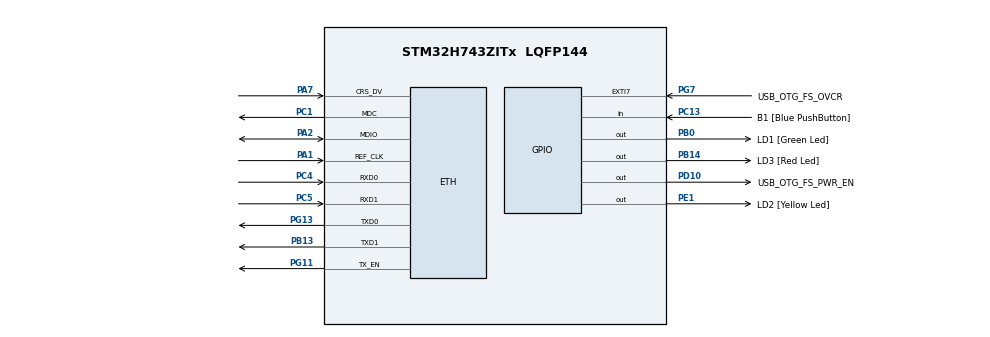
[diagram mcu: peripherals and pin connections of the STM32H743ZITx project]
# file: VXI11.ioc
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CORTEX_M7.AccessPermission_S-Cortex_Memory_Protection_Unit_Region1_Settings_S=MPU_REGION_FULL_ACCESS
CORTEX_M7.AccessPermission_S-Cortex_Memory_Protection_Unit_Region2_Settings_S=MPU_REGION_FULL_ACCESS
CORTEX_M7.BaseAddress_S-Cortex_Memory_Protection_Unit_Region1_Settings_S=0x30020000
CORTEX_M7.BaseAddress_S-Cortex_Memory_Protection_Unit_Region2_Settings_S=0x30040000
CORTEX_M7.CPU_DCache=Enabled
CORTEX_M7.CPU_ICache=Enabled
CORTEX_M7.DisableExec_S-Cortex_Memory_Protection_Unit_Region1_Settings_S=MPU_INSTRUCTION_ACCESS_DISABLE
CORTEX_M7.DisableExec_S-Cortex_Memory_Protection_Unit_Region2_Settings_S=MPU_INSTRUCTION_ACCESS_DISABLE
CORTEX_M7.Enable_S-Cortex_Memory_Protection_Unit_Region1_Settings_S=MPU_REGION_ENABLE
CORTEX_M7.Enable_S-Cortex_Memory_Protection_Unit_Region2_Settings_S=MPU_REGION_ENABLE
CORTEX_M7.IsBufferable_S-Cortex_Memory_Protection_Unit_Region2_Settings_S=MPU_ACCESS_BUFFERABLE
CORTEX_M7.IsShareable_S-Cortex_Memory_Protection_Unit_Region2_Settings_S=MPU_ACCESS_SHAREABLE
CORTEX_M7.Size_S-Cortex_Memory_Protection_Unit_Region1_Settings_S=MPU_REGION_SIZE_128KB
CORTEX_M7.Size_S-Cortex_Memory_Protection_Unit_Region2_Settings_S=MPU_REGION_SIZE_512B
CORTEX_M7.TypeExtField_S-Cortex_Memory_Protection_Unit_Region1_Settings_S=MPU_TEX_LEVEL1
CORTEX_M7.default_mode_Activation=1
ETH.MediaInterface=HAL_ETH_RMII_MODE
FREERTOS.Tasks01=defaultTask,0,512,StartDefaultTask,Default,NULL,Static,defaultTaskBuffer,defaultTaskControlBlock
FREERTOS.configENABLE_FPU=1
FREERTOS.configMINIMAL_STACK_SIZE=512
FREERTOS.configUSE_NEWLIB_REENTRANT=1
LWIP.BSP.number=1
LWIP.DEFAULT_THREAD_PRIO=6
LWIP.DEFAULT_THREAD_STACKSIZE=1024
LWIP.IP_ADDRESS=192.168.001.002
LWIP.LWIP_DHCP=0
LWIP.LWIP_RAM_HEAP_POINTER=0x30020000
LWIP.LWIP_SOCKET=0
LWIP.MEMP_NUM_LOCALHOSTLIST=1
LWIP.MEMP_NUM_PBUF=20
LWIP.MEMP_NUM_RAW_PCB=20
LWIP.MEMP_NUM_TCP_PCB=20
LWIP.MEMP_NUM_TCP_SEG=20
LWIP.MEMP_NUM_UDP_PCB=20
LWIP.MEM_SIZE=131048
LWIP.NETMASK_ADDRESS=255.255.255.000
LWIP.PBUF_POOL_BUFSIZE=1024
LWIP.TCPIP_MBOX_SIZE=12
LWIP.TCPIP_THREAD_PRIO=6
LWIP.TCPIP_THREAD_STACKSIZE=1024
LWIP.TCP_MSS=1460
LWIP.TCP_SND_BUF=5840
LWIP.TCP_SND_QUEUELEN=16
LWIP.TCP_WND=5840
LWIP.Version=v2.1.2_Cube
LWIP0.BSP.STBoard=false
LWIP0.BSP.api=BSP_COMPONENT_DRIVER
LWIP0.BSP.component=LAN8742
LWIP0.BSP.instance=LAN8742
LWIP0.BSP.name=Driver_PHY
LWIP0.BSP.semaphore=S_LAN8742
LWIP0.BSP.solution=LAN8742
Mcu.Family=STM32H7
Mcu.Name=STM32H743ZITx
Mcu.Package=LQFP144
NVIC.ETH_IRQn=true\:5\:0\:false\:false\:true\:true\:true\:true\:true
NVIC.PriorityGroup=NVIC_PRIORITYGROUP_4
NVIC.TIM1_UP_IRQn=true\:15\:0\:false\:false\:true\:false\:false\:true\:true
NVIC.TimeBase=TIM1_UP_IRQn
NVIC.TimeBaseIP=TIM1
PA1.GPIO_Speed=GPIO_SPEED_FREQ_VERY_HIGH
PA1.Mode=RMII
PA1.Signal=ETH_REF_CLK
PA11.Signal=USB_OTG_FS_DM
PA12.Signal=USB_OTG_FS_DP
PA2.GPIO_Speed=GPIO_SPEED_FREQ_VERY_HIGH
PA2.Mode=RMII
PA2.Signal=ETH_MDIO
PA7.GPIO_Speed=GPIO_SPEED_FREQ_VERY_HIGH
PA7.Mode=RMII
PA7.Signal=ETH_CRS_DV
PA8.Signal=USB_OTG_FS_SOF
PA9.Signal=USB_OTG_FS_VBUS
PB0.GPIO_Label=LD1 [Green Led]
PB0.Signal=GPIO_Output
PB13.GPIO_Speed=GPIO_SPEED_FREQ_VERY_HIGH
PB13.Mode=RMII
PB13.Signal=ETH_TXD1
PB14.GPIO_Label=LD3 [Red Led]
PB14.Signal=GPIO_Output
PC1.GPIO_Speed=GPIO_SPEED_FREQ_VERY_HIGH
PC1.Mode=RMII
PC1.Signal=ETH_MDC
PC13.GPIO_Label=B1 [Blue PushButton]
PC13.Signal=GPIO_Input
PC14-OSC32_IN\ (OSC32_IN).Mode=LSE-External-Oscillator
PC14-OSC32_IN\ (OSC32_IN).Signal=RCC_OSC32_IN
PC15-OSC32_OUT\ (OSC32_OUT).Mode=LSE-External-Oscillator
PC15-OSC32_OUT\ (OSC32_OUT).Signal=RCC_OSC32_OUT
PC4.GPIO_Speed=GPIO_SPEED_FREQ_VERY_HIGH
PC4.Mode=RMII
PC4.Signal=ETH_RXD0
PC5.GPIO_Speed=GPIO_SPEED_FREQ_VERY_HIGH
PC5.Mode=RMII
PC5.Signal=ETH_RXD1
PD10.GPIO_Label=USB_OTG_FS_PWR_EN
PD10.Signal=GPIO_Output
PD8.GPIO_Label=STLINK_RX
PD8.Signal=USART3_TX
PD9.GPIO_Label=STLINK_TX
PD9.Signal=USART3_RX
PE1.GPIO_Label=LD2 [Yellow Led]
PE1.Signal=GPIO_Output
PG11.GPIO_Speed=GPIO_SPEED_FREQ_VERY_HIGH
PG11.Mode=RMII
PG11.Signal=ETH_TX_EN
PG13.GPIO_Speed=GPIO_SPEED_FREQ_VERY_HIGH
PG13.Mode=RMII
PG13.Signal=ETH_TXD0
PG7.GPIO_Label=USB_OTG_FS_OVCR
PG7.Signal=GPXTI7
PH0-OSC_IN\ (PH0).Mode=HSE-External-Clock-Source
PH0-OSC_IN\ (PH0).Signal=RCC_OSC_IN
PH1-OSC_OUT\ (PH1).Signal=RCC_OSC_OUT
ProjectManager.HeapSize=0x200
ProjectManager.StackSize=0x400
ProjectManager.TargetToolchain=STM32CubeIDE
RCC.ADCFreq_Value=16125000
RCC.APB1Freq_Value=120000000
RCC.APB2Freq_Value=120000000
RCC.APB3Freq_Value=120000000
RCC.APB4Freq_Value=120000000
RCC.CortexFreq_Value=480000000
RCC.D1PPRE=RCC_APB3_DIV2
RCC.D2PPRE1=RCC_APB1_DIV2
RCC.D2PPRE2=RCC_APB2_DIV2
RCC.D3PPRE=RCC_APB4_DIV2
RCC.DIVM1=1
RCC.DIVN1=120
RCC.DIVQ1=4
RCC.HCLKFreq_Value=240000000
RCC.HPRE=RCC_HCLK_DIV2
RCC.HSE_VALUE=8000000
RCC.PLLFRACN=0
RCC.PLLSourceVirtual=RCC_PLLSOURCE_HSE
RCC.PWR_Regulator_Voltage_Scale=PWR_REGULATOR_VOLTAGE_SCALE0
RCC.SYSCLKFreq_VALUE=480000000
RCC.SYSCLKSource=RCC_SYSCLKSOURCE_PLLCLK
RCC.USBFreq_Value=240000000
VP_FREERTOS_VS_CMSIS_V1.Mode=CMSIS_V1
VP_LWIP_VS_Enabled.Mode=Enabled
VP_SYS_VS_tim1.Mode=TIM1
board=NUCLEO-H743ZI2

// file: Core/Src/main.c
/* USER CODE BEGIN Header */
/**
  ******************************************************************************
  * @file           : main.c
  * @brief          : Main program body
  ******************************************************************************
  * @attention
  *
  * Copyright (c) 2024 STMicroelectronics.
  * All rights reserved.
  *
  * This software is licensed under terms that can be found in the LICENSE file
  * in the root directory of this software component.
  * If no LICENSE file comes with this software, it is provided AS-IS.
  *
  ******************************************************************************
  */
/* USER CODE END Header */
#include "main.h"
#include "cmsis_os.h"
#include "lwip.h"

/* USER CODE BEGIN Includes */
#include "portmap.h"
#include "vxi11.h"
/* USER CODE END Includes */

osThreadId defaultTaskHandle;
uint32_t defaultTaskBuffer[ 512 ];
osStaticThreadDef_t defaultTaskControlBlock;

void SystemClock_Config(void);
static void MPU_Config(void);
static void MX_GPIO_Init(void);
void StartDefaultTask(void const * argument);

int main(void)
{

  /* MPU Configuration--------------------------------------------------------*/
  MPU_Config();

  /* Enable the CPU Cache */

  /* Enable I-Cache---------------------------------------------------------*/
  SCB_EnableICache();

  /* Enable D-Cache---------------------------------------------------------*/
  SCB_EnableDCache();

  /* MCU Configuration--------------------------------------------------------*/

  /* Reset of all peripherals, Initializes the Flash interface and the Systick. */
  HAL_Init();

  /* Configure the system clock */
  SystemClock_Config();

  /* Initialize all configured peripherals */
  MX_GPIO_Init();

  /* Create the thread(s) */
  /* definition and creation of defaultTask */
  osThreadStaticDef(defaultTask, StartDefaultTask, osPriorityNormal, 0, 512, defaultTaskBuffer, &defaultTaskControlBlock);
  defaultTaskHandle = osThreadCreate(osThread(defaultTask), NULL);

  /* Start scheduler */
  osKernelStart();

  /* We should never get here as control is now taken by the scheduler */

  /* Infinite loop */
  while (1)
  {

  }
}

void SystemClock_Config(void)
{
  LL_FLASH_SetLatency(LL_FLASH_LATENCY_4);
  while(LL_FLASH_GetLatency()!= LL_FLASH_LATENCY_4)
  {
  }
  LL_PWR_ConfigSupply(LL_PWR_LDO_SUPPLY);
  LL_PWR_SetRegulVoltageScaling(LL_PWR_REGU_VOLTAGE_SCALE0);
  while (LL_PWR_IsActiveFlag_VOS() == 0)
  {
  }
  LL_RCC_HSE_EnableBypass();
  LL_RCC_HSE_Enable();

   /* Wait till HSE is ready */
  while(LL_RCC_HSE_IsReady() != 1)
  {

  }
  LL_RCC_PLL_SetSource(LL_RCC_PLLSOURCE_HSE);
  LL_RCC_PLL1P_Enable();
  LL_RCC_PLL1_SetVCOInputRange(LL_RCC_PLLINPUTRANGE_8_16);
  LL_RCC_PLL1_SetVCOOutputRange(LL_RCC_PLLVCORANGE_WIDE);
  LL_RCC_PLL1_SetM(1);
  LL_RCC_PLL1_SetN(120);
  LL_RCC_PLL1_SetP(2);
  LL_RCC_PLL1_SetQ(4);
  LL_RCC_PLL1_SetR(2);
  LL_RCC_PLL1_Enable();

   /* Wait till PLL is ready */
  while(LL_RCC_PLL1_IsReady() != 1)
  {
  }

   /* Intermediate AHB prescaler 2 when target frequency clock is higher than 80 MHz */
   LL_RCC_SetAHBPrescaler(LL_RCC_AHB_DIV_2);

  LL_RCC_SetSysClkSource(LL_RCC_SYS_CLKSOURCE_PLL1);

   /* Wait till System clock is ready */
  while(LL_RCC_GetSysClkSource() != LL_RCC_SYS_CLKSOURCE_STATUS_PLL1)
  {

  }
  LL_RCC_SetSysPrescaler(LL_RCC_SYSCLK_DIV_1);
  LL_RCC_SetAHBPrescaler(LL_RCC_AHB_DIV_2);
  LL_RCC_SetAPB1Prescaler(LL_RCC_APB1_DIV_2);
  LL_RCC_SetAPB2Prescaler(LL_RCC_APB2_DIV_2);
  LL_RCC_SetAPB3Prescaler(LL_RCC_APB3_DIV_2);
  LL_RCC_SetAPB4Prescaler(LL_RCC_APB4_DIV_2);
  LL_SetSystemCoreClock(480000000);

   /* Update the time base */
  if (HAL_InitTick (TICK_INT_PRIORITY) != HAL_OK)
  {
    Error_Handler();
  }
}

static void MX_GPIO_Init(void)
{
  LL_EXTI_InitTypeDef EXTI_InitStruct = {0};
  LL_GPIO_InitTypeDef GPIO_InitStruct = {0};

  /* GPIO Ports Clock Enable */
  LL_AHB4_GRP1_EnableClock(LL_AHB4_GRP1_PERIPH_GPIOC);
  LL_AHB4_GRP1_EnableClock(LL_AHB4_GRP1_PERIPH_GPIOH);
  LL_AHB4_GRP1_EnableClock(LL_AHB4_GRP1_PERIPH_GPIOA);
  LL_AHB4_GRP1_EnableClock(LL_AHB4_GRP1_PERIPH_GPIOB);
  LL_AHB4_GRP1_EnableClock(LL_AHB4_GRP1_PERIPH_GPIOD);
  LL_AHB4_GRP1_EnableClock(LL_AHB4_GRP1_PERIPH_GPIOG);
  LL_AHB4_GRP1_EnableClock(LL_AHB4_GRP1_PERIPH_GPIOE);

  /**/
  LL_GPIO_ResetOutputPin(GPIOB, LD1_Pin|LD3_Pin);

  /**/
  LL_GPIO_ResetOutputPin(USB_OTG_FS_PWR_EN_GPIO_Port, USB_OTG_FS_PWR_EN_Pin);

  /**/
  LL_GPIO_ResetOutputPin(LD2_GPIO_Port, LD2_Pin);

  /**/
  GPIO_InitStruct.Pin = B1_Pin;
  GPIO_InitStruct.Mode = LL_GPIO_MODE_INPUT;
  GPIO_InitStruct.Pull = LL_GPIO_PULL_NO;
  LL_GPIO_Init(B1_GPIO_Port, &GPIO_InitStruct);

  /**/
  GPIO_InitStruct.Pin = LD1_Pin|LD3_Pin;
  GPIO_InitStruct.Mode = LL_GPIO_MODE_OUTPUT;
  GPIO_InitStruct.Speed = LL_GPIO_SPEED_FREQ_LOW;
  GPIO_InitStruct.OutputType = LL_GPIO_OUTPUT_PUSHPULL;
  GPIO_InitStruct.Pull = LL_GPIO_PULL_NO;
  LL_GPIO_Init(GPIOB, &GPIO_InitStruct);

  /**/
  GPIO_InitStruct.Pin = STLINK_RX_Pin|STLINK_TX_Pin;
  GPIO_InitStruct.Mode = LL_GPIO_MODE_ALTERNATE;
  GPIO_InitStruct.Speed = LL_GPIO_SPEED_FREQ_LOW;
  GPIO_InitStruct.OutputType = LL_GPIO_OUTPUT_PUSHPULL;
  GPIO_InitStruct.Pull = LL_GPIO_PULL_NO;
  GPIO_InitStruct.Alternate = LL_GPIO_AF_7;
  LL_GPIO_Init(GPIOD, &GPIO_InitStruct);

  /**/
  GPIO_InitStruct.Pin = USB_OTG_FS_PWR_EN_Pin;
  GPIO_InitStruct.Mode = LL_GPIO_MODE_OUTPUT;
  GPIO_InitStruct.Speed = LL_GPIO_SPEED_FREQ_LOW;
  GPIO_InitStruct.OutputType = LL_GPIO_OUTPUT_PUSHPULL;
  GPIO_InitStruct.Pull = LL_GPIO_PULL_NO;
  LL_GPIO_Init(USB_OTG_FS_PWR_EN_GPIO_Port, &GPIO_InitStruct);

  /**/
  GPIO_InitStruct.Pin = LL_GPIO_PIN_8|LL_GPIO_PIN_11|LL_GPIO_PIN_12;
  GPIO_InitStruct.Mode = LL_GPIO_MODE_ALTERNATE;
  GPIO_InitStruct.Speed = LL_GPIO_SPEED_FREQ_LOW;
  GPIO_InitStruct.OutputType = LL_GPIO_OUTPUT_PUSHPULL;
  GPIO_InitStruct.Pull = LL_GPIO_PULL_NO;
  GPIO_InitStruct.Alternate = LL_GPIO_AF_10;
  LL_GPIO_Init(GPIOA, &GPIO_InitStruct);

  /**/
  GPIO_InitStruct.Pin = LD2_Pin;
  GPIO_InitStruct.Mode = LL_GPIO_MODE_OUTPUT;
  GPIO_InitStruct.Speed = LL_GPIO_SPEED_FREQ_LOW;
  GPIO_InitStruct.OutputType = LL_GPIO_OUTPUT_PUSHPULL;
  GPIO_InitStruct.Pull = LL_GPIO_PULL_NO;
  LL_GPIO_Init(LD2_GPIO_Port, &GPIO_InitStruct);

  /**/
  LL_SYSCFG_SetEXTISource(LL_SYSCFG_EXTI_PORTG, LL_SYSCFG_EXTI_LINE7);

  /**/
  EXTI_InitStruct.Line_0_31 = LL_EXTI_LINE_7;
  EXTI_InitStruct.Line_32_63 = LL_EXTI_LINE_NONE;
  EXTI_InitStruct.Line_64_95 = LL_EXTI_LINE_NONE;
  EXTI_InitStruct.LineCommand = ENABLE;
  EXTI_InitStruct.Mode = LL_EXTI_MODE_IT;
  EXTI_InitStruct.Trigger = LL_EXTI_TRIGGER_RISING;
  LL_EXTI_Init(&EXTI_InitStruct);

  /**/
  LL_GPIO_SetPinPull(USB_OTG_FS_OVCR_GPIO_Port, USB_OTG_FS_OVCR_Pin, LL_GPIO_PULL_NO);

  /**/
  LL_GPIO_SetPinMode(USB_OTG_FS_OVCR_GPIO_Port, USB_OTG_FS_OVCR_Pin, LL_GPIO_MODE_INPUT);

}

void StartDefaultTask(void const * argument)
{
  /* init code for LWIP */
  MX_LWIP_Init();
  /* USER CODE BEGIN 5 */
  osDelay(pdMS_TO_TICKS(100));

  vxi11_server_start();
  pmap_server_start();

  /* Infinite loop */
  for(;;)
  {
	//  HAL_GPIO_TogglePin(LD1_GPIO_Port, LD1_Pin);
	  osDelay(pdMS_TO_TICKS(10));
  }
  /* USER CODE END 5 */
}

 /* MPU Configuration */

void MPU_Config(void)
{

  /* Disables the MPU */
  LL_MPU_Disable();

  /** Initializes and configures the Region and the memory to be protected
  */
  LL_MPU_ConfigRegion(LL_MPU_REGION_NUMBER0, 0x87, 0x0, LL_MPU_REGION_SIZE_4GB|LL_MPU_TEX_LEVEL0|LL_MPU_REGION_NO_ACCESS|LL_MPU_INSTRUCTION_ACCESS_DISABLE|LL_MPU_ACCESS_SHAREABLE|LL_MPU_ACCESS_NOT_CACHEABLE|LL_MPU_ACCESS_NOT_BUFFERABLE);

  /** Initializes and configures the Region and the memory to be protected
  */
  LL_MPU_ConfigRegion(LL_MPU_REGION_NUMBER1, 0x0, 0x30020000, LL_MPU_REGION_SIZE_128KB|LL_MPU_TEX_LEVEL1|LL_MPU_REGION_FULL_ACCESS|LL_MPU_INSTRUCTION_ACCESS_DISABLE|LL_MPU_ACCESS_NOT_SHAREABLE|LL_MPU_ACCESS_NOT_CACHEABLE|LL_MPU_ACCESS_NOT_BUFFERABLE);

  /** Initializes and configures the Region and the memory to be protected
  */
  LL_MPU_ConfigRegion(LL_MPU_REGION_NUMBER2, 0x0, 0x30040000, LL_MPU_REGION_SIZE_512B|LL_MPU_TEX_LEVEL0|LL_MPU_REGION_FULL_ACCESS|LL_MPU_INSTRUCTION_ACCESS_DISABLE|LL_MPU_ACCESS_SHAREABLE|LL_MPU_ACCESS_NOT_CACHEABLE|LL_MPU_ACCESS_BUFFERABLE);
  /* Enables the MPU */
  LL_MPU_Enable(LL_MPU_CTRL_PRIVILEGED_DEFAULT);

}

void HAL_TIM_PeriodElapsedCallback(TIM_HandleTypeDef *htim)
{
  if (htim->Instance == TIM1) {
    HAL_IncTick();
  }
}

void Error_Handler(void)
{
  __disable_irq();
  while (1)
  {
  }
}
